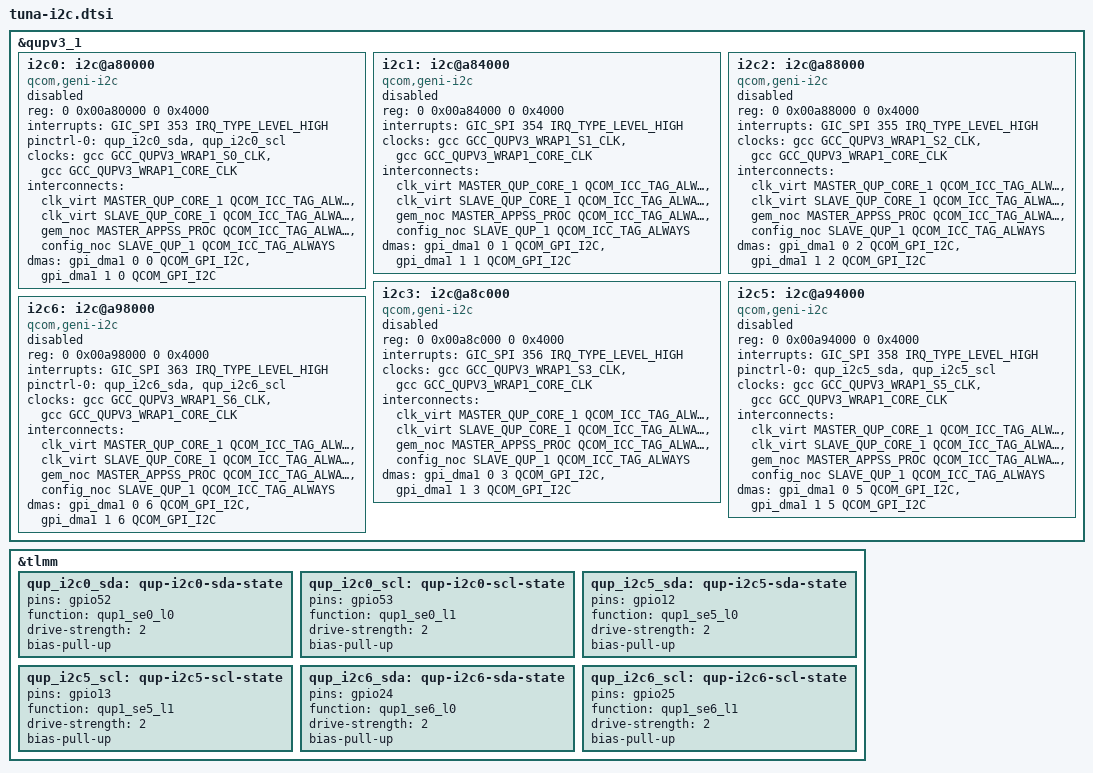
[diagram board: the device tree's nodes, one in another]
// SPDX-License-Identifier: BSD-3-Clause
/*
 * Meizu 22 (M2582) -- QUPV3 wrap 1 I2C controllers (0xac0000).
 *
 * SE1 (0xa84000) and SE6 (0xa98000) are not mapped to the application
 * processor (reading their windows raises a synchronous external abort) and
 * must remain disabled. Every instance declares both "se" and "core" clocks
 * as well as the qup-core interconnect vote so the wrap-1 core clock stays
 * ungated across transfers.
 */

#include <dt-bindings/dma/qcom-gpi.h>

&qupv3_1 {
	i2c0: i2c@a80000 {
		compatible = "qcom,geni-i2c";
		reg = <0 0x00a80000 0 0x4000>;
		interrupts = <GIC_SPI 353 IRQ_TYPE_LEVEL_HIGH>;
		/*
		 * SDA/SCL on gpio52/gpio53. SE1 and SE6 are not mapped for the
		 * application processor at all -- the first register access to
		 * either raises a synchronous external abort -- so this is the
		 * bus to use.
		 */
		pinctrl-names = "default";
		pinctrl-0 = <&qup_i2c0_sda>, <&qup_i2c0_scl>;
		clocks = <&gcc GCC_QUPV3_WRAP1_S0_CLK>, <&gcc GCC_QUPV3_WRAP1_CORE_CLK>;
		interconnects = <&clk_virt MASTER_QUP_CORE_1 QCOM_ICC_TAG_ALWAYS
				 &clk_virt SLAVE_QUP_CORE_1 QCOM_ICC_TAG_ALWAYS>,
				<&gem_noc MASTER_APPSS_PROC QCOM_ICC_TAG_ALWAYS
				 &config_noc SLAVE_QUP_1 QCOM_ICC_TAG_ALWAYS>;
		interconnect-names = "qup-core", "qup-config";
		clock-names = "se", "core";
		dmas = <&gpi_dma1 0 0 QCOM_GPI_I2C>,
		       <&gpi_dma1 1 0 QCOM_GPI_I2C>;
		dma-names = "tx", "rx";
		#address-cells = <1>;
		#size-cells = <0>;
		status = "disabled";
	};

	i2c1: i2c@a84000 {
		compatible = "qcom,geni-i2c";
		reg = <0 0x00a84000 0 0x4000>;
		interrupts = <GIC_SPI 354 IRQ_TYPE_LEVEL_HIGH>;
		clocks = <&gcc GCC_QUPV3_WRAP1_S1_CLK>, <&gcc GCC_QUPV3_WRAP1_CORE_CLK>;
		interconnects = <&clk_virt MASTER_QUP_CORE_1 QCOM_ICC_TAG_ALWAYS
				 &clk_virt SLAVE_QUP_CORE_1 QCOM_ICC_TAG_ALWAYS>,
				<&gem_noc MASTER_APPSS_PROC QCOM_ICC_TAG_ALWAYS
				 &config_noc SLAVE_QUP_1 QCOM_ICC_TAG_ALWAYS>;
		interconnect-names = "qup-core", "qup-config";
		clock-names = "se", "core";
		dmas = <&gpi_dma1 0 1 QCOM_GPI_I2C>,
		       <&gpi_dma1 1 1 QCOM_GPI_I2C>;
		dma-names = "tx", "rx";
		#address-cells = <1>;
		#size-cells = <0>;
		status = "disabled";
	};

	i2c2: i2c@a88000 {
		compatible = "qcom,geni-i2c";
		reg = <0 0x00a88000 0 0x4000>;
		interrupts = <GIC_SPI 355 IRQ_TYPE_LEVEL_HIGH>;
		clocks = <&gcc GCC_QUPV3_WRAP1_S2_CLK>, <&gcc GCC_QUPV3_WRAP1_CORE_CLK>;
		interconnects = <&clk_virt MASTER_QUP_CORE_1 QCOM_ICC_TAG_ALWAYS
				 &clk_virt SLAVE_QUP_CORE_1 QCOM_ICC_TAG_ALWAYS>,
				<&gem_noc MASTER_APPSS_PROC QCOM_ICC_TAG_ALWAYS
				 &config_noc SLAVE_QUP_1 QCOM_ICC_TAG_ALWAYS>;
		interconnect-names = "qup-core", "qup-config";
		clock-names = "se", "core";
		dmas = <&gpi_dma1 0 2 QCOM_GPI_I2C>,
		       <&gpi_dma1 1 2 QCOM_GPI_I2C>;
		dma-names = "tx", "rx";
		#address-cells = <1>;
		#size-cells = <0>;
		status = "disabled";
	};

	i2c3: i2c@a8c000 {
		compatible = "qcom,geni-i2c";
		reg = <0 0x00a8c000 0 0x4000>;
		interrupts = <GIC_SPI 356 IRQ_TYPE_LEVEL_HIGH>;
		clocks = <&gcc GCC_QUPV3_WRAP1_S3_CLK>, <&gcc GCC_QUPV3_WRAP1_CORE_CLK>;
		interconnects = <&clk_virt MASTER_QUP_CORE_1 QCOM_ICC_TAG_ALWAYS
				 &clk_virt SLAVE_QUP_CORE_1 QCOM_ICC_TAG_ALWAYS>,
				<&gem_noc MASTER_APPSS_PROC QCOM_ICC_TAG_ALWAYS
				 &config_noc SLAVE_QUP_1 QCOM_ICC_TAG_ALWAYS>;
		interconnect-names = "qup-core", "qup-config";
		clock-names = "se", "core";
		dmas = <&gpi_dma1 0 3 QCOM_GPI_I2C>,
		       <&gpi_dma1 1 3 QCOM_GPI_I2C>;
		dma-names = "tx", "rx";
		#address-cells = <1>;
		#size-cells = <0>;
		status = "disabled";
	};

	/*
	 * SE4 is not an I2C bus on this board: the phone's own aliases make it
	 * spi4 (spi@a90000), and that is where its touchscreen is -- a
	 * Synaptics TCM part on chip select 0.  The runtime device tree has it
	 * as SPI, and the bootloader leaves the engine programmed the same way.
	 * The node itself is in meizu-m2582-touch.dtsi, beside the device on it,
	 * because the pads and the supplies are board facts.
	 */

	/*
	 * SE5: i2c5 (i2c@a94000), gpio12/gpio13 (qup1_se5_l0/l1).
	 * The runtime tree carries two smart PAs (fs1945@34, fs1945@35) here.
	 */
	i2c5: i2c@a94000 {
		compatible = "qcom,geni-i2c";
		reg = <0 0x00a94000 0 0x4000>;
		interrupts = <GIC_SPI 358 IRQ_TYPE_LEVEL_HIGH>;
		pinctrl-names = "default";
		pinctrl-0 = <&qup_i2c5_sda>, <&qup_i2c5_scl>;
		clocks = <&gcc GCC_QUPV3_WRAP1_S5_CLK>,
			 <&gcc GCC_QUPV3_WRAP1_CORE_CLK>;
		clock-names = "se", "core";
		interconnects = <&clk_virt MASTER_QUP_CORE_1 QCOM_ICC_TAG_ALWAYS
				 &clk_virt SLAVE_QUP_CORE_1 QCOM_ICC_TAG_ALWAYS>,
				<&gem_noc MASTER_APPSS_PROC QCOM_ICC_TAG_ALWAYS
				 &config_noc SLAVE_QUP_1 QCOM_ICC_TAG_ALWAYS>;
		interconnect-names = "qup-core", "qup-config";
		dmas = <&gpi_dma1 0 5 QCOM_GPI_I2C>,
		       <&gpi_dma1 1 5 QCOM_GPI_I2C>;
		dma-names = "tx", "rx";
		#address-cells = <1>;
		#size-cells = <0>;
		status = "disabled";
	};

	i2c6: i2c@a98000 {
		compatible = "qcom,geni-i2c";
		reg = <0 0x00a98000 0 0x4000>;
		interrupts = <GIC_SPI 363 IRQ_TYPE_LEVEL_HIGH>;
		pinctrl-names = "default";
		pinctrl-0 = <&qup_i2c6_sda>, <&qup_i2c6_scl>;
		clocks = <&gcc GCC_QUPV3_WRAP1_S6_CLK>, <&gcc GCC_QUPV3_WRAP1_CORE_CLK>;
		interconnects = <&clk_virt MASTER_QUP_CORE_1 QCOM_ICC_TAG_ALWAYS
				 &clk_virt SLAVE_QUP_CORE_1 QCOM_ICC_TAG_ALWAYS>,
				<&gem_noc MASTER_APPSS_PROC QCOM_ICC_TAG_ALWAYS
				 &config_noc SLAVE_QUP_1 QCOM_ICC_TAG_ALWAYS>;
		interconnect-names = "qup-core", "qup-config";
		clock-names = "se", "core";
		dmas = <&gpi_dma1 0 6 QCOM_GPI_I2C>,
		       <&gpi_dma1 1 6 QCOM_GPI_I2C>;
		dma-names = "tx", "rx";
		#address-cells = <1>;
		#size-cells = <0>;
		status = "disabled";
	};
};

&tlmm {
	qup_i2c0_sda: qup-i2c0-sda-state {
		pins = "gpio52";
		function = "qup1_se0_l0";
		drive-strength = <2>;
		bias-pull-up;
	};

	qup_i2c0_scl: qup-i2c0-scl-state {
		pins = "gpio53";
		function = "qup1_se0_l1";
		drive-strength = <2>;
		bias-pull-up;
	};

	qup_i2c5_sda: qup-i2c5-sda-state {
		pins = "gpio12";
		function = "qup1_se5_l0";
		drive-strength = <2>;
		bias-pull-up;
	};

	qup_i2c5_scl: qup-i2c5-scl-state {
		pins = "gpio13";
		function = "qup1_se5_l1";
		drive-strength = <2>;
		bias-pull-up;
	};

	qup_i2c6_sda: qup-i2c6-sda-state {
		pins = "gpio24";
		function = "qup1_se6_l0";
		drive-strength = <2>;
		bias-pull-up;
	};

	qup_i2c6_scl: qup-i2c6-scl-state {
		pins = "gpio25";
		function = "qup1_se6_l1";
		drive-strength = <2>;
		bias-pull-up;
	};
};
